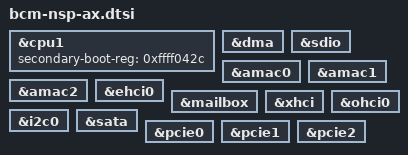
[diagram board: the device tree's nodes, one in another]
// SPDX-License-Identifier: GPL-2.0-or-later OR MIT
/*
 * Broadcom Northstar Plus Ax stepping-specific bindings.
 * Notable differences from B0+ are the secondary-boot-reg and
 * lack of DMA coherency.
 */

&cpu1 {
	secondary-boot-reg = <0xffff042c>;
};

&dma {
	/delete-property/ dma-coherent;
};

&sdio {
	/delete-property/ dma-coherent;
};

&amac0 {
	/delete-property/ dma-coherent;
};

&amac1 {
	/delete-property/ dma-coherent;
};

&amac2 {
	/delete-property/ dma-coherent;
};

&ehci0 {
	/delete-property/ dma-coherent;
};

&mailbox {
	/delete-property/ dma-coherent;
};

&xhci {
	/delete-property/ dma-coherent;
};

&ehci0 {
	/delete-property/ dma-coherent;
};

&ohci0 {
	/delete-property/ dma-coherent;
};

&i2c0 {
	/delete-property/ dma-coherent;
};

&sata {
	/delete-property/ dma-coherent;
};

&pcie0 {
	/delete-property/ dma-coherent;
};

&pcie1 {
	/delete-property/ dma-coherent;
};

&pcie2 {
	/delete-property/ dma-coherent;
};
